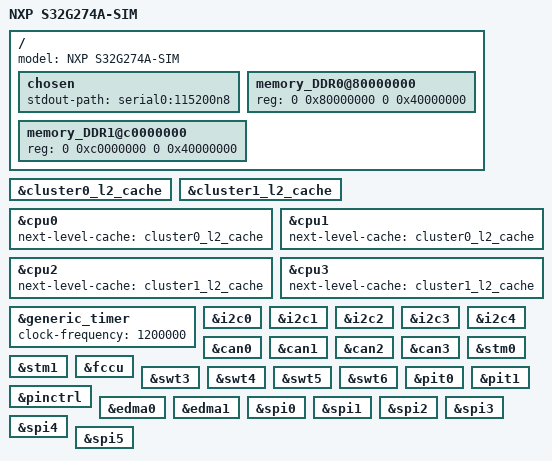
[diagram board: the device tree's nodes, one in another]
/*
 * Copyright 2017-2022 NXP
 *
 * This program is free software; you can redistribute it and/or modify
 * it under the terms of the GNU General Public License as published by
 * the Free Software Foundation; either version 2 of the License, or
 * (at your option) any later version.
 */

/dts-v1/;
#include "s32g2.dtsi"
#include <dt-bindings/pinctrl/s32g-pinctrl.h>
/ {
	model = "NXP S32G274A-SIM";

	chosen {
		stdout-path = "serial0:115200n8";
	};

	memory_DDR0@80000000 {
		device_type = "memory";
		reg = <0 0x80000000 0 0x40000000>;
	};

	memory_DDR1@c0000000 {
		device_type = "memory";
		reg = <0 0xc0000000 0 0x40000000>;
	};
};

&cluster0_l2_cache {
	status = "okay";
};

&cluster1_l2_cache {
	status = "okay";
};

&cpu0 {
	next-level-cache = <&cluster0_l2_cache>;
};

&cpu1 {
	next-level-cache = <&cluster0_l2_cache>;
};

&cpu2 {
	next-level-cache = <&cluster1_l2_cache>;
};

&cpu3 {
	next-level-cache = <&cluster1_l2_cache>;
};

&generic_timer {
	clock-frequency = <1200000>;
};

&i2c0 {
	status = "okay";
};

&i2c1 {
	status = "okay";
};

&i2c2 {
	status = "okay";
};

&i2c3 {
	status = "okay";
};

&i2c4 {
	status = "okay";
};

&can0 {
	status = "okay";
};

&can1 {
	status = "okay";
};

&can2 {
	status = "okay";
};

&can3 {
	status = "okay";
};

&stm0 {
	status = "okay";
};

&stm1 {
	status = "okay";
};

&fccu {
	status = "okay";
};

&swt3 {
	status = "okay";
};

&swt4 {
	status = "okay";
};

&swt5 {
	status = "okay";
};

&swt6 {
	status = "okay";
};

&pit0 {
	status = "okay";
};

&pit1 {
	status = "okay";
};

&pinctrl {
	status = "okay";
};

&edma0 {
	status = "okay";
};

&edma1 {
	status = "okay";
};

&spi0 {
	status = "okay";
};

&spi1 {
	status = "okay";
};

&spi2 {
	status = "okay";
};

&spi3 {
	status = "okay";
};

&spi4 {
	status = "okay";
};

&spi5 {
	status = "okay";
};
